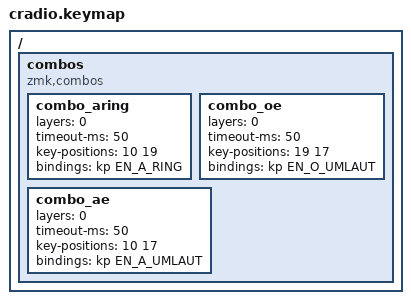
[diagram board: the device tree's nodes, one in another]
// Copyright 2021 Manna Harbour
// https://github.com/manna-harbour/miryoku

#include "../miryoku/custom_config.h"
#include "../miryoku/mapping/34/ferris.h"
#include "../miryoku/miryoku.dtsi"

#include "keys_us_international.h"

/ {
    combos {
        compatible = "zmk,combos";
      combo_aring{
          layers = <0>;
          timeout-ms = <50>;
          key-positions = <10 19>;
          bindings = <&kp EN_A_RING>;
        };
      combo_oe{
          layers = <0>;
          timeout-ms = <50>;
          key-positions = <19 17>;
          bindings = <&kp EN_O_UMLAUT>;
        };
        combo_ae {
            layers = <0>;
            timeout-ms = <50>;
            key-positions = <10 17>;
            bindings = <&kp EN_A_UMLAUT>;
        };
    };
};
